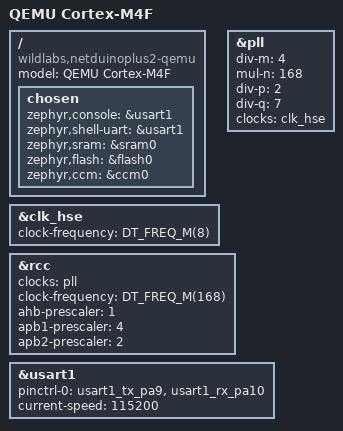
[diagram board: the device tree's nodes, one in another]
/*
 * Copyright (c) 2020 Stephanos Ioannidis <root@stephanos.io>
 *
 * SPDX-License-Identifier: Apache-2.0
 */

/dts-v1/;
#include <st/f4/stm32f405Xg.dtsi>
#include <st/f4/stm32f405rgtx-pinctrl.dtsi>

/ {
	model = "QEMU Cortex-M4F";
	compatible = "wildlabs,netduinoplus2-qemu";

	chosen {
		zephyr,console = &usart1;
		zephyr,shell-uart = &usart1;
		zephyr,sram = &sram0;
		zephyr,flash = &flash0;
		zephyr,ccm = &ccm0;
	};
};

&clk_hse {
	clock-frequency = <DT_FREQ_M(8)>;
	status = "okay";
};

&pll {
	div-m = <4>;
	mul-n = <168>;
	div-p = <2>;
	div-q = <7>;
	clocks = <&clk_hse>;
	status = "okay";
};

&rcc {
	clocks = <&pll>;
	clock-frequency = <DT_FREQ_M(168)>;
	ahb-prescaler = <1>;
	apb1-prescaler = <4>;
	apb2-prescaler = <2>;
};

&usart1 {
	pinctrl-0 = <&usart1_tx_pa9 &usart1_rx_pa10>;
	current-speed = <115200>;
	status = "okay";
};
